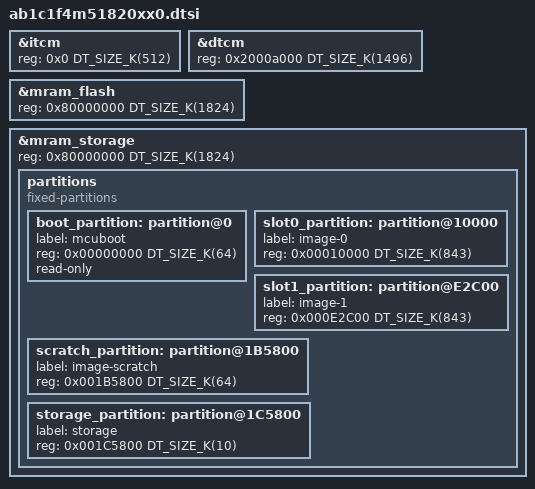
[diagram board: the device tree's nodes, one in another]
/* Copyright (c) 2025 Alif Semiconductor
 *
 * SPDX-License-Identifier: Apache-2.0
 */

#include <alif/balletto/common/b1.dtsi>

&itcm {
	reg = <0x0 DT_SIZE_K(512)>;
};

&dtcm {
	/* total dtcm(1536) - reserved dtcm(40) */
	reg = <0x2000a000 DT_SIZE_K(1496)>;
};

&mram_flash {
	/* Usable MRAM size for applications is 1824 KB */
	reg = <0x80000000 DT_SIZE_K(1824)>;
};

&mram_storage {
	reg = <0x80000000 DT_SIZE_K(1824)>;
};

&mram_storage {
	partitions {
		compatible = "fixed-partitions";
		#address-cells = <1>;
		#size-cells = <1>;

		boot_partition: partition@0 {
			label = "mcuboot";
			reg = <0x00000000 DT_SIZE_K(64)>;
			read-only;
		};

		slot0_partition: partition@10000 {
			label = "image-0";
			reg = <0x00010000 DT_SIZE_K(843)>;
		};

		slot1_partition: partition@E2C00 {
			label = "image-1";
			reg = <0x000E2C00 DT_SIZE_K(843)>;
		};

		scratch_partition: partition@1B5800 {
			label = "image-scratch";
			reg = <0x001B5800 DT_SIZE_K(64)>;
		};

		storage_partition: partition@1C5800 {
			label = "storage";
			reg = <0x001C5800 DT_SIZE_K(10)>;
		};
	};
};
